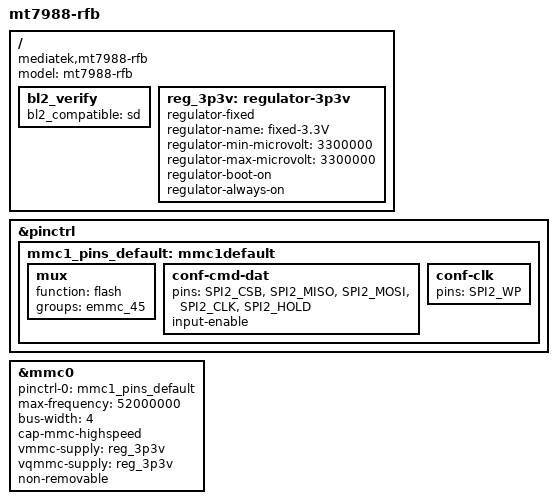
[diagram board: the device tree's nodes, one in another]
// SPDX-License-Identifier: GPL-2.0
/*
 * Copyright (c) 2022 MediaTek Inc.
 * Author: Sam Shih <sam.shih@mediatek.com>
 */

/dts-v1/;
#include "mt7988-rfb.dts"
#include <dt-bindings/gpio/gpio.h>

/ {
	model = "mt7988-rfb";
	compatible = "mediatek,mt7988-rfb", "mediatek,mt7988-sd-rfb";

	bl2_verify {
		bl2_compatible = "sd";
	};

	reg_3p3v: regulator-3p3v {
		compatible = "regulator-fixed";
		regulator-name = "fixed-3.3V";
		regulator-min-microvolt = <3300000>;
		regulator-max-microvolt = <3300000>;
		regulator-boot-on;
		regulator-always-on;
	};
};

&pinctrl {
	mmc1_pins_default: mmc1default {
		mux {
			function = "flash";
			groups =  "emmc_45";
		};

		conf-cmd-dat {
			pins = "SPI2_CSB", "SPI2_MISO", "SPI2_MOSI",
			       "SPI2_CLK", "SPI2_HOLD";
			input-enable;
		};

		conf-clk {
			pins = "SPI2_WP";
		};
	};
};

&mmc0 {
	pinctrl-names = "default";
	pinctrl-0 = <&mmc1_pins_default>;
	max-frequency = <52000000>;
	bus-width = <4>;
	cap-mmc-highspeed;
	vmmc-supply = <&reg_3p3v>;
	vqmmc-supply = <&reg_3p3v>;
	non-removable;
	status = "okay";
};
